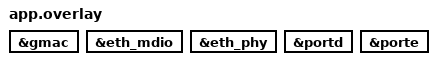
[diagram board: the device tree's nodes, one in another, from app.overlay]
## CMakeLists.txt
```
# Copyright (c) 2026
# SPDX-License-Identifier: Apache-2.0

cmake_minimum_required(VERSION 3.20.0)

# Custom board (../boards/microchip/mega_can) and the repo's Zephyr module
# (../module: the PIC32CZ Ethernet driver), without west manifest changes.
list(APPEND BOARD_ROOT ${CMAKE_CURRENT_SOURCE_DIR}/..)
list(APPEND ZEPHYR_EXTRA_MODULES ${CMAKE_CURRENT_SOURCE_DIR}/../module)

find_package(Zephyr REQUIRED HINTS $ENV{ZEPHYR_BASE})
project(mega_can_ethtest)

target_sources(app PRIVATE src/main.c)
```

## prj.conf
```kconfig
CONFIG_GPIO=y
CONFIG_PRINTK=y
CONFIG_LOG=y
CONFIG_MAIN_STACK_SIZE=2048

# The Ethernet driver does no cache maintenance on packet buffers yet
# (upstream targeted a Cortex-M4 without a D-cache). See the driver header.
CONFIG_DCACHE=n

CONFIG_NETWORKING=y
CONFIG_NET_L2_ETHERNET=y
CONFIG_ETH_DRIVER=y
CONFIG_MDIO=y
CONFIG_NET_IPV4=y
CONFIG_NET_IPV6=n
CONFIG_NET_UDP=y
CONFIG_NET_TCP=n
CONFIG_NET_SOCKETS=y

# Board = 192.168.10.2, Jetson/laptop = 192.168.10.1 (udp_protocol/README.md)
CONFIG_NET_CONFIG_SETTINGS=y
CONFIG_NET_CONFIG_NEED_IPV4=y
CONFIG_NET_CONFIG_MY_IPV4_ADDR="192.168.10.2"
CONFIG_NET_CONFIG_MY_IPV4_NETMASK="255.255.255.0"
CONFIG_NET_CONFIG_PEER_IPV4_ADDR="192.168.10.1"
# don't hold boot waiting for a cable
CONFIG_NET_CONFIG_INIT_TIMEOUT=0

# Driver error counters (CRC, alignment, ...) = the gigabit timing check.
CONFIG_NET_STATISTICS=y
CONFIG_NET_STATISTICS_ETHERNET=y

# "net iface", "net stats", "net ping 192.168.10.1" on the UART console
CONFIG_SHELL=y
CONFIG_NET_SHELL=y

CONFIG_NET_LOG=y
CONFIG_ETHERNET_LOG_LEVEL_INF=y
CONFIG_PHY_LOG_LEVEL_INF=y

# No TRNG entropy driver for PIC32CZ CA in Zephyr yet; the net stack needs
# random numbers for ports/IDs. Not cryptographic, fine on the robot's
# closed network. Replace when there's a TRNG driver.
CONFIG_TEST_RANDOM_GENERATOR=y
```

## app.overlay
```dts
/* Ethernet on: MAC, bit-banged MDIO, KSZ9031 PHY (see the included file). */
#include "../boards/microchip/mega_can/mega_can-gmac.dtsi"

&gmac {
	status = "okay";
};

&eth_mdio {
	status = "okay";
};

&eth_phy {
	status = "okay";
};

/* straps, RX pins (port D) and PHY reset PE7 (port E) */
&portd {
	status = "okay";
};

&porte {
	status = "okay";
};
```

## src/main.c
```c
/*
 * Copyright (c) 2026
 * SPDX-License-Identifier: Apache-2.0
 *
 * mega_can Ethernet bench test, the step after phyprobe/.
 *
 * Brings up the ETH MAC + KSZ9031 with the PIC32CZ driver from ../module, at
 * 192.168.10.2/24. Then:
 *   - answers ping (the IPv4 stack does that by itself)
 *   - echoes every UDP datagram sent to port 7 back to its sender
 *   - LED toggles once a second
 * The driver logs "link up: 1000/100 Mbit/s ..." on every link change.
 *
 * From the Jetson/laptop at 192.168.10.1:
 *   ping 192.168.10.2
 *   echo hello | nc -u -w1 192.168.10.2 7
 * On the board's UART shell (115200):
 *   net iface     link, speed, addresses
 *   net stats     packet and error counters (CRC errors should stay 0)
 *
 * NOTE on running: the factory boot ROM halts at a BKPT when a debugger is
 * attached; reset with the probe's nRESET (or power-cycle) to run.
 */

#include <zephyr/kernel.h>
#include <zephyr/drivers/gpio.h>
#include <zephyr/net/socket.h>
#include <zephyr/sys/printk.h>

#define ECHO_PORT 7

static const struct gpio_dt_spec led = GPIO_DT_SPEC_GET(DT_ALIAS(led0), gpios);

static void blink(void *a, void *b, void *c)
{
	ARG_UNUSED(a);
	ARG_UNUSED(b);
	ARG_UNUSED(c);

	while (1) {
		gpio_pin_toggle_dt(&led);
		k_msleep(1000);
	}
}

K_THREAD_DEFINE(blink_tid, 512, blink, NULL, NULL, NULL, 7, 0, 0);

int main(void)
{
	struct sockaddr_in addr = {
		.sin_family = AF_INET,
		.sin_port = htons(ECHO_PORT),
		.sin_addr.s_addr = htonl(INADDR_ANY),
	};
	static uint8_t buf[1500];
	int sock;

	gpio_pin_configure_dt(&led, GPIO_OUTPUT_INACTIVE);
	printk("\nmega_can ethtest: 192.168.10.2, UDP echo on port %d\n", ECHO_PORT);

	sock = zsock_socket(AF_INET, SOCK_DGRAM, IPPROTO_UDP);
	if (sock < 0) {
		printk("socket() failed: %d\n", errno);
		return 0;
	}
	if (zsock_bind(sock, (struct sockaddr *)&addr, sizeof(addr)) < 0) {
		printk("bind() failed: %d\n", errno);
		return 0;
	}

	while (1) {
		struct sockaddr_in from;
		socklen_t from_len = sizeof(from);
		int len = zsock_recvfrom(sock, buf, sizeof(buf), 0, (struct sockaddr *)&from,
					 &from_len);

		if (len < 0) {
			printk("recvfrom() failed: %d\n", errno);
			k_msleep(100);
			continue;
		}
		zsock_sendto(sock, buf, len, 0, (struct sockaddr *)&from, from_len);
	}
	return 0;
}
```
